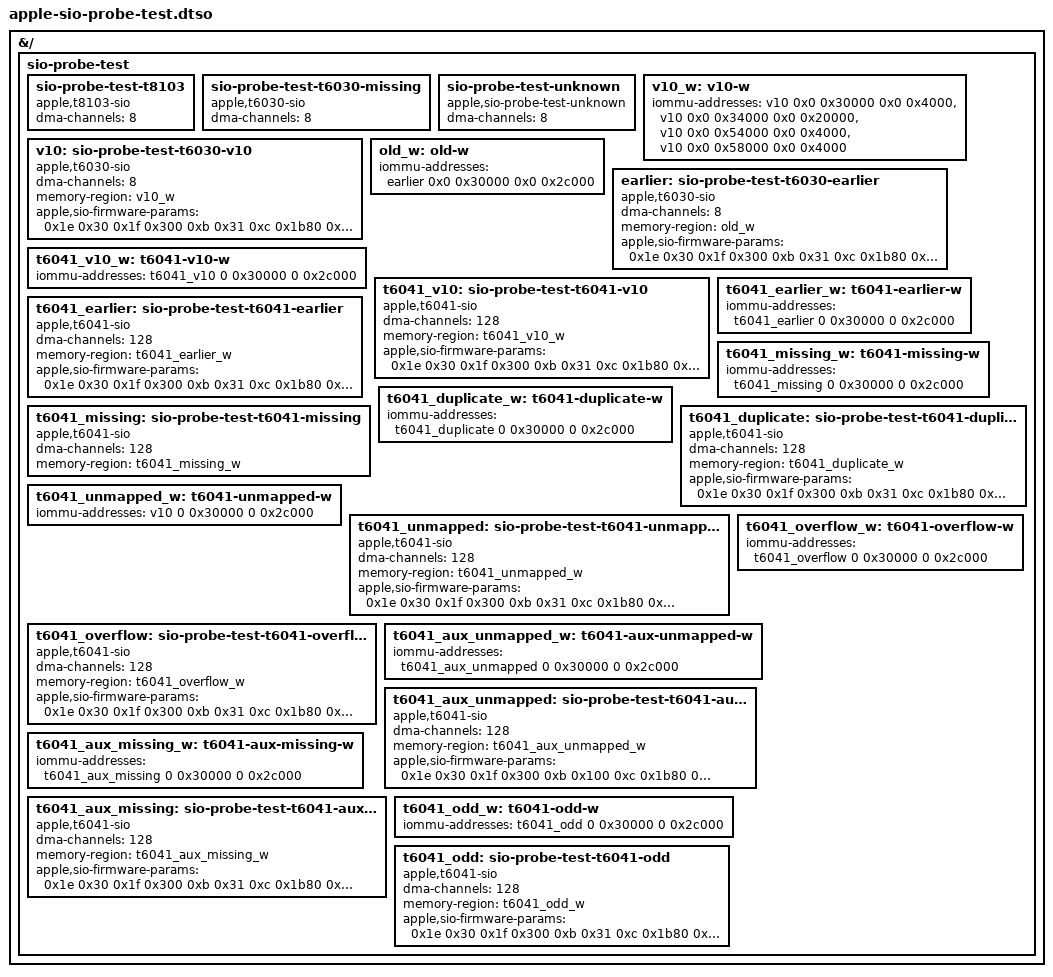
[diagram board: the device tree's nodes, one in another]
// SPDX-License-Identifier: GPL-2.0-only OR MIT
/dts-v1/;
/plugin/;

/*
 * SIO nodes for the probe test: an M1 one, and T6030 ones with the tables of a
 * T6030-aware boot loader and of an earlier one. The container is not a bus, so
 * nothing binds to them; the test calls the probe itself.
 */
&{/} {
	sio-probe-test {
		#address-cells = <2>;
		#size-cells = <2>;

		sio-probe-test-t8103 {
			compatible = "apple,t8103-sio", "apple,sio";
			dma-channels = <8>;
		};

		sio-probe-test-t6030-missing {
			compatible = "apple,t6030-sio", "apple,sio";
			dma-channels = <8>;
		};

		sio-probe-test-unknown {
			compatible = "apple,sio-probe-test-unknown";
			dma-channels = <8>;
		};

		v10_w: v10-w {
			iommu-addresses = <&v10 0x0 0x30000 0x0 0x4000>, <&v10 0x0 0x34000 0x0 0x20000>,
					  <&v10 0x0 0x54000 0x0 0x4000>, <&v10 0x0 0x58000 0x0 0x4000>;
		};

		v10: sio-probe-test-t6030-v10 {
			compatible = "apple,t6030-sio", "apple,sio";
			dma-channels = <8>;
			memory-region = <&v10_w>;
			apple,sio-firmware-params = <0x1e 0x30 0x1f 0x300 0xb 0x31 0xc 0x1b80
						     0xf 0x34 0x10 0x1e000 0x30d 0x54 0x30e 0x4000
						     0x1a 0x58 0x1b 0x40 0x22 0x59 0x23 0xd8
						     0x1c 0x5a 0x1d 0x48>;
		};

		old_w: old-w { iommu-addresses = <&earlier 0x0 0x30000 0x0 0x2c000>; };

		earlier: sio-probe-test-t6030-earlier {
			compatible = "apple,t6030-sio", "apple,sio";
			dma-channels = <8>;
			memory-region = <&old_w>;
			apple,sio-firmware-params = <0x1e 0x30 0x1f 0x300 0xb 0x31 0xc 0x1b80
						     0xf 0x34 0x10 0x1e000 0x30d 0x54 0x30e 0x4000
						     0x1a 0x58 0x1b 0x40 0x22 0x59 0x23 0xa0
						     0x1c 0x5a 0x1d 0x40>;
		};
		t6041_v10_w: t6041-v10-w {
			iommu-addresses = <&t6041_v10 0 0x30000 0 0x2c000>;
		};
		t6041_v10: sio-probe-test-t6041-v10 {
			compatible = "apple,t6041-sio";
			dma-channels = <128>;
			memory-region = <&t6041_v10_w>;
			apple,sio-firmware-params = <0x1e 0x30 0x1f 0x300 0xb 0x31 0xc 0x1b80 0xf 0x34 0x10 0x1e000 0x30d 0x54 0x30e 0x4000 0x1a 0x58 0x1b 0x40 0x22 0x59 0x23 0xd8 0x1c 0x5a 0x1d 0x48>;
		};

		t6041_earlier_w: t6041-earlier-w {
			iommu-addresses = <&t6041_earlier 0 0x30000 0 0x2c000>;
		};
		t6041_earlier: sio-probe-test-t6041-earlier {
			compatible = "apple,t6041-sio";
			dma-channels = <128>;
			memory-region = <&t6041_earlier_w>;
			apple,sio-firmware-params = <0x1e 0x30 0x1f 0x300 0xb 0x31 0xc 0x1b80 0xf 0x34 0x10 0x1e000 0x30d 0x54 0x30e 0x4000 0x1a 0x58 0x1b 0x40 0x22 0x59 0x23 0xa0 0x1c 0x5a 0x1d 0x40>;
		};

		t6041_missing_w: t6041-missing-w {
			iommu-addresses = <&t6041_missing 0 0x30000 0 0x2c000>;
		};
		t6041_missing: sio-probe-test-t6041-missing {
			compatible = "apple,t6041-sio";
			dma-channels = <128>;
			memory-region = <&t6041_missing_w>;

		};

		t6041_duplicate_w: t6041-duplicate-w {
			iommu-addresses = <&t6041_duplicate 0 0x30000 0 0x2c000>;
		};
		t6041_duplicate: sio-probe-test-t6041-duplicate {
			compatible = "apple,t6041-sio";
			dma-channels = <128>;
			memory-region = <&t6041_duplicate_w>;
			apple,sio-firmware-params = <0x1e 0x30 0x1f 0x300 0xb 0x31 0xc 0x1b80 0xf 0x34 0x10 0x1e000 0x30d 0x54 0x30e 0x4000 0x1a 0x58 0x1b 0x40 0x22 0x59 0x23 0xd8 0x1c 0x5a 0x1d 0x48 0x22 0x59>;
		};

		t6041_unmapped_w: t6041-unmapped-w {
			iommu-addresses = <&v10 0 0x30000 0 0x2c000>;
		};
		t6041_unmapped: sio-probe-test-t6041-unmapped {
			compatible = "apple,t6041-sio";
			dma-channels = <128>;
			memory-region = <&t6041_unmapped_w>;
			apple,sio-firmware-params = <0x1e 0x30 0x1f 0x300 0xb 0x31 0xc 0x1b80 0xf 0x34 0x10 0x1e000 0x30d 0x54 0x30e 0x4000 0x1a 0x58 0x1b 0x40 0x22 0x59 0x23 0xd8 0x1c 0x5a 0x1d 0x48>;
		};

		t6041_overflow_w: t6041-overflow-w {
			iommu-addresses = <&t6041_overflow 0 0x30000 0 0x2c000>;
		};
		t6041_overflow: sio-probe-test-t6041-overflow {
			compatible = "apple,t6041-sio";
			dma-channels = <128>;
			memory-region = <&t6041_overflow_w>;
			apple,sio-firmware-params = <0x1e 0x30 0x1f 0x300 0xb 0x31 0xc 0x1b80 0xf 0x34 0x10 0x1e000 0x30d 0x54 0x30e 0x4000 0x1a 0x58 0x1b 0x40 0x22 0xffffffff 0x23 0xd8 0x1c 0x5a 0x1d 0x48>;
		};

		t6041_aux_unmapped_w: t6041-aux-unmapped-w {
			iommu-addresses = <&t6041_aux_unmapped 0 0x30000 0 0x2c000>;
		};
		t6041_aux_unmapped: sio-probe-test-t6041-aux-unmapped {
			compatible = "apple,t6041-sio";
			dma-channels = <128>;
			memory-region = <&t6041_aux_unmapped_w>;
			apple,sio-firmware-params = <0x1e 0x30 0x1f 0x300 0xb 0x100 0xc 0x1b80 0xf 0x34 0x10 0x1e000 0x30d 0x54 0x30e 0x4000 0x1a 0x58 0x1b 0x40 0x22 0x59 0x23 0xd8 0x1c 0x5a 0x1d 0x48>;
		};

		t6041_aux_missing_w: t6041-aux-missing-w {
			iommu-addresses = <&t6041_aux_missing 0 0x30000 0 0x2c000>;
		};
		t6041_aux_missing: sio-probe-test-t6041-aux-missing {
			compatible = "apple,t6041-sio";
			dma-channels = <128>;
			memory-region = <&t6041_aux_missing_w>;
			apple,sio-firmware-params = <0x1e 0x30 0x1f 0x300 0xb 0x31 0xc 0x1b80 0xf 0x34 0x10 0x1e000 0x1a 0x58 0x1b 0x40 0x22 0x59 0x23 0xd8 0x1c 0x5a 0x1d 0x48>;
		};

		t6041_odd_w: t6041-odd-w {
			iommu-addresses = <&t6041_odd 0 0x30000 0 0x2c000>;
		};
		t6041_odd: sio-probe-test-t6041-odd {
			compatible = "apple,t6041-sio";
			dma-channels = <128>;
			memory-region = <&t6041_odd_w>;
			apple,sio-firmware-params = <0x1e 0x30 0x1f 0x300 0xb 0x31 0xc 0x1b80 0xf 0x34 0x10 0x1e000 0x30d 0x54 0x30e 0x4000 0x1a 0x58 0x1b 0x40 0x22 0x59 0x23 0xd8 0x1c 0x5a 0x1d 0x48 0x41>;
		};

	};
};
